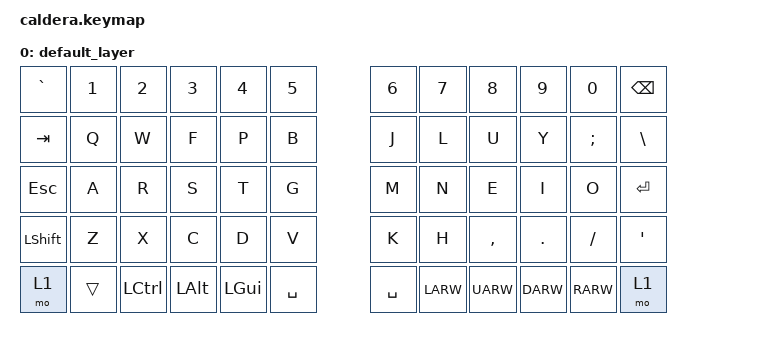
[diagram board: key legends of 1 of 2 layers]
/*
 * Copyright (c) 2020 The ZMK Contributors
 *
 * SPDX-License-Identifier: MIT
 */
 
#include <behaviors.dtsi>
#include <dt-bindings/zmk/keys.h>
#include <dt-bindings/zmk/bt.h>

/ {
        keymap {
                compatible = "zmk,keymap";

                default_layer {
// ---------------------------------------------------------------------------------
// |   `  |  1  |   2  |  3  |  4  |  5  |     |  6  |  7  |  8  |  9  |  0  | BKSP |
// | TAB  |  Q  |   W  |  F  |  P  |  B  |     |  J  |  L  |  U  |  Y  |  ;  |  \   |
// | ESC  |  A  |   R  |  S  |  T  |  G  |     |  M  |  N  |  E  |  I  |  O  |  ENT |
// | SHFT |  Z  |   X  |  C  |  D  |  V  |     |  K  |  H  |  ,  |  .  |  /  |   '  |
// | LOW  |     | CTRL | ALT | GUI | SPC |     | SPC |LARW |UARW |DARW |RARW |  LOW |
                        bindings = <
   &kp GRAVE  &kp N1    &kp N2    &kp N3     &kp N4     &kp N5               &kp N6     &kp N7    &kp N8     &kp N9    &kp N0    &kp BSPC
   &kp TAB    &kp Q     &kp W     &kp F      &kp P      &kp B                &kp J      &kp L     &kp U      &kp Y     &kp SEMI  &kp BSLH
   &kp ESC    &kp A     &kp R     &kp S      &kp T      &kp G                &kp M      &kp N     &kp E      &kp I     &kp O     &kp RET
   &kp LSHFT  &kp Z     &kp X     &kp C      &kp D      &kp V                &kp K      &kp H     &kp COMMA  &kp DOT   &kp FSLH  &kp APOS
   &mo 1      &trans    &kp LCTRL &kp LALT   &kp LGUI   &kp SPACE            &kp SPACE  &kp LARW  &kp UARW   &kp DARW  &kp RARW  &mo 1 
                        >;
                };
                lower_layer {
// ------------------------------------------------------------------------------------        ------------------------------------------------------------------
// |       |  BT1         |      BT2      |     BT3      |     BT4      |     BT5     |        |       |           |         |           |    -     |     =     |
// |       |              |               |    LPAR      |    RPAR      |             |        |       |   LBKT    |   RBKT  |           |          |           |
// |       |              |               |    LARW      |    UARW      |      J      |        |   K   |   DARW    |   RARW  |           |          |           |
// |       |              |               |              |              |      H      |        |   L   |           |         |           |          | BTCLR     |
                        bindings = <
   &trans    &bt BT_SEL 0   &bt BT_SEL 1   &bt BT_SEL 2   &bt BT_SEL 3   &bt BT_SEL 4           &trans    &trans     &trans    &trans      &kp MINUS   &kp EQUAL
   &trans    &trans         &trans         &kp LPAR       &kp RPAR       &trans                 &trans    &kp LBKT   &kp RBKT  &trans      &trans      &trans
   &trans    &trans         &trans         &kp LARW       &kp UARW       &kp J                  &kp K     &kp DARW   &kp RARW  &trans      &trans      &trans
   &trans    &trans         &trans         &trans         &trans         &kp H                  &kp L     &kp K      &kp L     &trans      &trans      &bt BT_CLR
                        >;
                };
        };
};



